VERSION ""

NS_ :

BS_:

BU_: TCU Ambient_Light Ambient_Light_ECU Panel_ECU

BO_ 336 msg_light_output: 1 Ambient_Light_ECU
 SG_ ambient_light_color_cmd : 6|3@0+ (1,0) [0|7] ""  Ambient_Light
 SG_ ambient_light_onoff : 7|1@0+ (1,0) [0|1] ""  Ambient_Light

BO_ 320 msg_tcu_res: 1 TCU
 SG_ ambient_purchase_list : 7|8@0+ (1,0) [0|255] ""  Ambient_Light_ECU,Panel_ECU

BO_ 304 msg_tcu_req: 1 Ambient_Light_ECU
 SG_ ambient_purchase_list_req : 0|1@0+ (1,0) [0|1] ""  TCU

BO_ 288 msg_ambient_ctrl: 2 Ambient_Light_ECU
 SG_ ambient_current_color : 10|3@0+ (1,0) [0|7] ""  Panel_ECU
 SG_ ambient_unlock_status : 7|8@0+ (1,0) [0|255] ""  Panel_ECU

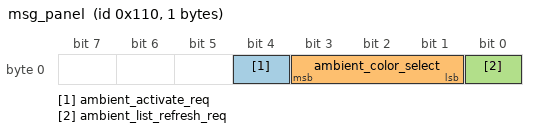
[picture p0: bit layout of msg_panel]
BO_ 272 msg_panel: 1 Panel_ECU
 SG_ ambient_activate_req : 4|1@0+ (1,0) [0|1] ""  Ambient_Light_ECU
 SG_ ambient_color_select : 3|3@0+ (1,0) [0|7] ""  Ambient_Light_ECU
 SG_ ambient_list_refresh_req : 0|1@0+ (1,0) [0|1] ""  Ambient_Light_ECU

EV_ EnvKlemme30: 0 [0|1] "" 1 1 DUMMY_NODE_VECTOR0 Vector__XXX;

EV_ EnvKlemme15: 0 [0|1] "" 0 2 DUMMY_NODE_VECTOR0 Vector__XXX;

BA_DEF_ BU_  "NodeLayerModules" STRING ;
BA_DEF_ BO_  "GenMsgILSupport" ENUM  "No","Yes";
BA_DEF_  "NmBaseAddress" HEX 1024 1087;
BA_DEF_ BO_  "GenMsgSendType" ENUM  "Cyclic","NotUsed","NotUsed","NotUsed","NotUsed","NotUsed","NotUsed","IfActive","NoMsgSendType","NotUsed","vector_leerstring";
BA_DEF_ SG_  "GenSigSendType" ENUM  "Cyclic","OnWrite","OnWriteWithRepetition","OnChange","OnChangeWithRepetition","IfActive","IfActiveWithRepetition","NoSigSendType","NotUsed","NotUsed","NotUsed","NotUsed","NotUsed";
BA_DEF_DEF_  "NodeLayerModules" "CANoeILNLVector.dll";
BA_DEF_DEF_  "GenMsgILSupport" "Yes";
BA_DEF_DEF_  "NmBaseAddress" 1024;
BA_DEF_DEF_  "GenMsgSendType" "NoMsgSendType";
BA_DEF_DEF_  "GenSigSendType" "Cyclic";
